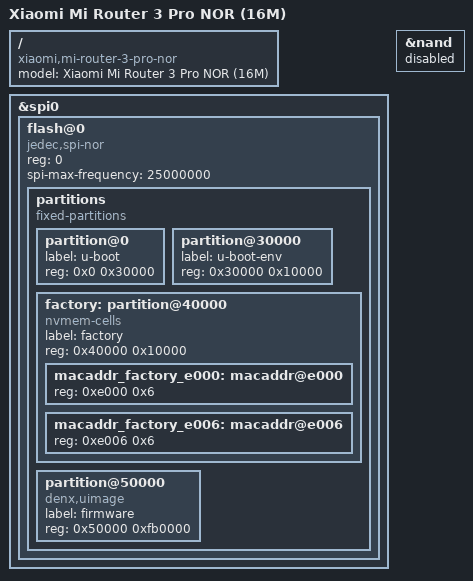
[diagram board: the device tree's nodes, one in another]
#include "mt7621_xiaomi_mi-router-3-pro.dts"

/ {
	compatible = "xiaomi,mi-router-3-pro-nor", "mediatek,mt7621-soc";
	model = "Xiaomi Mi Router 3 Pro NOR (16M)";
};

&spi0 {
	status = "okay";

	flash@0 {
		compatible = "jedec,spi-nor";
		reg = <0>;
		spi-max-frequency = <25000000>;

		partitions {
			compatible = "fixed-partitions";
			#address-cells = <1>;
			#size-cells = <1>;

			partition@0 {
				label = "u-boot";
				reg = <0x0 0x30000>;
			};

			partition@30000 {
				label = "u-boot-env";
				reg = <0x30000 0x10000>;
			};

			factory: partition@40000 {
				label = "factory";
				reg = <0x40000 0x10000>;
			};

			partition@50000 {
				compatible = "denx,uimage";
				label = "firmware";
				reg = <0x50000 0xfb0000>;
			};
		};
	};
};

&nand {
	status = "disabled";
	/delete-node/ partitions;
};

&factory {
	compatible = "nvmem-cells";
	#address-cells = <1>;
	#size-cells = <1>;

	macaddr_factory_e000: macaddr@e000 {
		reg = <0xe000 0x6>;
	};

	macaddr_factory_e006: macaddr@e006 {
		reg = <0xe006 0x6>;
	};
};
